# M051DN_v1 register map
File version: 1.0
Registers are 32-bit, read-write, reset 0x0 unless marked. A register's access mark holds for its fields unless they carry their own. Offsets are from the block's base; [hi:lo] are bit positions; {n}, {i} and the like mark numbered series.

## UART0 — UART Register Map
Base 0x40050000
Same registers: UART1 0x40150000
0x00 UA_RBR ro reset not defined — UART Receive Buffer Register
  [7:0] RBR — Receive Buffer Register (Read Only). By reading this register, the UART Controller will return an 8-bit data received from UART_RX pin (LSB first).
0x00 UA_THR wo reset not defined (alternate view of UA_RBR) — UART Transmit Holding Register
  [7:0] THR — Transmit Holding Register. By writing to this register, the UART Controller will send out an 8-bit data through the UART_ TX pin (LSB first).
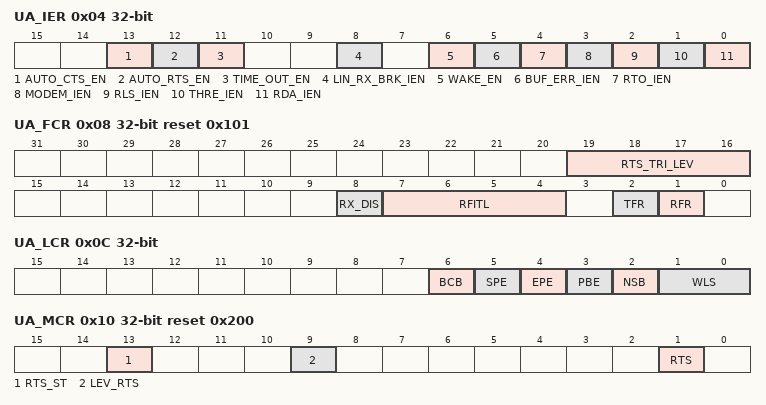
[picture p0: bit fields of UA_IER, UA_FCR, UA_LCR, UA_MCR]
0x04 UA_IER — UART Interrupt Enable Register
  [13] AUTO_CTS_EN — CTS Auto-flow Control Enable Control. Note: When CTS auto-flow is enabled, the UART will send data to external device when CTS input assert (UART will not send data to device until CTS is asserted).
    0=CTS auto-flow control Disabled; 1=CTS auto-flow control Enabled
  [12] AUTO_RTS_EN — RTS Auto-flow Control Enable Control. Note: When RTS auto-flow is enabled, if the number of bytes in the RX FIFO equals the RTS_TRI_LEV (UA_FCR [19:16]), the UART will reassert RTS signal.
    0=RTS auto-flow control Disabled; 1=RTS auto-flow control Enabled
  [11] TIME_OUT_EN — Time-out Counter Enable Control
    0=Time-out counter Disabled; 1=Time-out counter Enabled
  [8] LIN_RX_BRK_IEN — LIN RX Break Field Detected Interrupt Enable Control. Note: This bit is used for LIN function mode.
    0=LIN bus RX break filed interrupt Disabled; 1=LIN bus RX break filed interrupt Enabled
  [6] WAKE_EN — UART Wake-up Function Enable Control. Note: when the chip is in Power-down mode, an external CTS change will wake-up chip from Power-down mode.
    0=UART wake-up function Disabled; 1=UART wake-up function Enabled
  [5] BUF_ERR_IEN — Buffer Error Interrupt Enable Control
    0=BUF_ERR_INT Masked off; 1=BUF_ERR_INT Enabled
  [4] RTO_IEN — RX Time-out Interrupt Enable Control
    0=TOUT_INT Masked off; 1=TOUT_INT Enabled
  [3] MODEM_IEN — Modem Status Interrupt Enable Control
    0=MODEM_INT Masked off; 1=MODEM_INT Enabled
  [2] RLS_IEN — Receive Line Status Interrupt Enable Control
    0=RLS_INT Masked off; 1=RLS_INT Enabled
  [1] THRE_IEN — Transmit Holding Register Empty Interrupt Enable Control
    0=THRE_INT Masked off; 1=THRE_INT Enabled
  [0] RDA_IEN — Receive Data Available Interrupt Enable Control
    0=RDA_INT Masked off; 1=RDA_INT Enabled
0x08 UA_FCR reset 0x101 — UART FIFO Control Register
  [19:16] RTS_TRI_LEV — RTS Trigger Level (for Auto-flow Control Use). Note: This field is used for RTS auto-flow control.
    0=RTS Trigger Level is 1 byte; 1=RTS Trigger Level is 4 bytes; 2=RTS Trigger Level is 8 bytes; 3=RTS Trigger Level is 14 bytes
  [8] RX_DIS — Receiver Disable Register. The receiver is disabled or not (set 1 to disable receiver). Note: This field is used for RS-485 Normal Multi-drop mode. It should be programmed before RS-485_NMM (UA_ALT_CSR [8]) is programmed.
    0=Receiver Enabled; 1=Receiver Disabled
  [7:4] RFITL — RX FIFO Interrupt (RDA_INT) Trigger Level. When the number of bytes in the receive FIFO equals the RFITL then the RDA_IF will be set (if RDA_IEN in UA_IER register is enable, an interrupt will generated).
    0=RX FIFO Interrupt Trigger Level is 1 byte; 1=RX FIFO Interrupt Trigger Level is 4 bytes; 2=RX FIFO Interrupt Trigger Level is 8 bytes; 3=RX FIFO Interrupt Trigger Level is 14 bytes
  [2] TFR — TX Field Software Reset. When TX_RST is set, all the byte in the transmit FIFO and TX internal state machine are cleared. Note: This bit will automatically clear at least 3 UART Controller peripheral clock cycles.
    0=No effect; 1=Reset the TX internal state machine and pointers
  [1] RFR — RX Field Software Reset. When RX_RST is set, all the byte in the receiver FIFO and RX internal state machine are cleared. Note: This bit will automatically clear at least 3 UART Controller peripheral clock cycles.
    0=No effect; 1=Reset the RX internal state machine and pointers
0x0C UA_LCR — UART Line Control Register
  [6] BCB — Break Control Bit. When this bit is set to logic 1, the serial data output (TX) is forced to the Spacing State (logic 0). This bit acts only on TX and has no effect on the transmitter logic.
    0=Break control Disabled; 1=Break control Enabled
  [5] SPE — Stick Parity Enable Control
    0=Stick parity Disabled; 1=If PBE (UA_LCR[3]) and EBE (UA_LCR[4]) are logic 1, the parity bit is transmitted and checked as logic 0. If PBE (UA_LCR[3]) is 1 and EBE (UA_LCR[4]) is 0 then the parity bit is transmitted and checked as 1
  [4] EPE — Even Parity Enable Control. This bit has effect only when PBE (UA_LCR[3]) is set.
    0=Odd number of logic 1's is transmitted and checked in each word; 1=Even number of logic 1's is transmitted and checked in each word
  [3] PBE — Parity Bit Enable Control
    0=No parity bit; 1=Parity bit is generated on each outgoing character and is checked on each incoming data
  [2] NSB — Number of "STOP Bit"
    0=One "STOP bit" is generated in the transmitted data; 1=When select 5-bit word length, 1.5 "STOP bit" is generated in the transmitted data. When select 6-, 7- and 8-bti word length, 2 "STOP bit" is generated in the transmitted data
  [1:0] WLS — Word Length Selection
    {v}=Word length is {v+5}-bit (v=0..3)
0x10 UA_MCR reset 0x200 — UART Modem Control Register
  [13] RTS_ST ro — RTS Pin Status (Read Only). This bit mirror from RTS pin output of voltage logic status.
    0=RTS pin output is low level voltage logic state; 1=RTS pin output is high level voltage logic state
  [9] LEV_RTS — RTS Pin Active Level. This bit defines the active level state of RTS pin output. Note1: Refer to Figure 664 and Figure 665 for UART function mode. Note2: Refer to Figure 669 and Figure 670 for RS-485 function mode.
    0=RTS pin output is high level active; 1=RTS pin output is low level active
  [1] RTS — RTS (Request-to-send) Signal Control. This bit is direct control internal RTS signal active or not, and then drive the RTS pin output with LEV_RTS bit configuration. Note1: This RTS signal control bit is not effective when RTS auto-flow control is enabled in UART function mode. Note2: This RTS signal control bit is not effective when RS-485 auto direction mode (AUD) is enabled in RS-485 function mode.
    0=RTS signal is active; 1=RTS signal is inactive
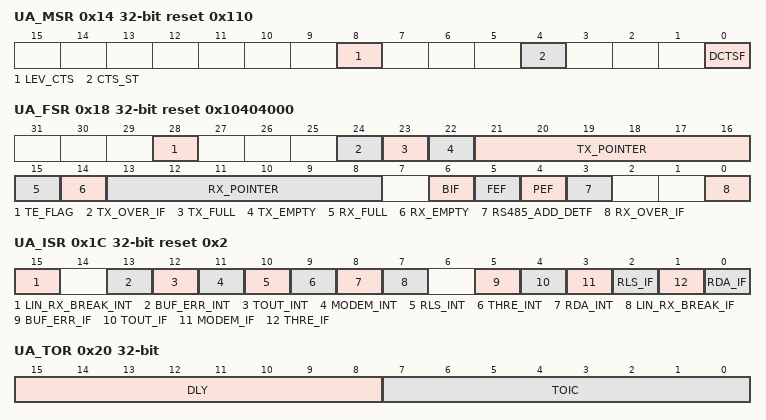
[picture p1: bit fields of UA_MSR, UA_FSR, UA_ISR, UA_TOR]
0x14 UA_MSR reset 0x110 — UART Modem Status Register
  [8] LEV_CTS — CTS Pin Active Level. This bit defines the active level state of CTS pin input. Note: Refer to Figure 663 for more information.
    0=CTS pin input is high level active; 1=CTS pin input is low level active
  [4] CTS_ST ro — CTS Pin Status (Read Only). This bit mirror from CTS pin input of voltage logic status. Note: This bit echoes when UART Controller peripheral clock is enabled, and CTS multi-function port is selected.
    0=CTS pin input is low level voltage logic state; 1=CTS pin input is high level voltage logic state
  [0] DCTSF — Detect CTS State Change Flag. This bit is set whenever CTS input has change state, and it will generate Modem interrupt to CPU when MODEM_IEN (UA_IER [3]) is set to 1. Note: This bit is cleared by writing 1 to it.
    0=CTS input has not change state; 1=CTS input has change state
0x18 UA_FSR reset 0x10404000 — UART FIFO Status Register
  [28] TE_FLAG ro — Transmitter Empty Flag (Read Only). This bit is set by hardware when TX FIFO (UA_THR) is empty and the STOP bit of the last byte has been transmitted. Note: This bit is cleared automatically when TX FIFO is not empty or the last byte transmission has not completed.
    0=TX FIFO is not empty; 1=TX FIFO is empty
  [24] TX_OVER_IF — TX Overflow Error Interrupt Flag. If TX FIFO (UA_THR) is full, an additional write to UA_THR will cause this bit to logic 1. Note: This bit is cleared by writing 1 to it.
    0=TX FIFO is not overflow; 1=TX FIFO is overflow
  [23] TX_FULL ro — Transmitter FIFO Full (Read Only). This bit indicates TX FIFO full or not. Note: This bit is set when the number of usage in TX FIFO Buffer is equal to 16, otherwise is cleared by hardware.
    0=TX FIFO is not full; 1=TX FIFO is full
  [22] TX_EMPTY ro — Transmitter FIFO Empty (Read Only). This bit indicates TX FIFO empty or not. Note: When the last byte of TX FIFO has been transferred to Transmitter Shift Register, hardware sets this bit high. It will be cleared when writing data into THR (TX FIFO not empty).
    0=TX FIFO is not empty; 1=TX FIFO is empty
  [21:16] TX_POINTER ro — TX FIFO Pointer (Read Only). This field indicates the TX FIFO Buffer Pointer. When CPU writes one byte into UA_THR, TX_POINTER increases one. When one byte of TX FIFO is transferred to Transmitter Shift Register, TX_POINTER decreases one. The Maximum value shown in TX_POINTER is 15. When the using level of TX FIFO Buffer equal to 16, the TX_FULL bit is set to 1 and TX_POINTER will show 0. As one byte of TX FIFO is transferred to Transmitter Shift Register, the TX_FULL bit is cleared to 0 and TX_POINTER will show 15.
  [15] RX_FULL ro — Receiver FIFO Full (Read Only). This bit initiates RX FIFO full or not. Note: This bit is set when the number of usage in RX FIFO Buffer is equal to 16, otherwise is cleared by hardware.
    0=RX FIFO is not full; 1=RX FIFO is full
  [14] RX_EMPTY ro — Receiver FIFO Empty (Read Only). This bit initiate RX FIFO empty or not. Note: When the last byte of RX FIFO has been read by CPU, hardware sets this bit high. It will be cleared when UART receives any new data.
    0=RX FIFO is not empty; 1=RX FIFO is empty
  [13:8] RX_POINTER ro — RX FIFO Pointer (Read Only). This field indicates the RX FIFO Buffer Pointer. When UART receives one byte from external device, RX_POINTER increases one. When one byte of RX FIFO is read by CPU, RX_POINTER decreases one. The Maximum value shown in RX_POINTER is 15. When the using level of RX FIFO Buffer equal to 16, the RX_FULL bit is set to 1 and RX_POINTER will show 0. As one byte of RX FIFO is read by CPU, the RX_FULL bit is cleared to 0 and RX_POINTER will show 15.
  [6] BIF ro — Break Interrupt Flag (Read Only). This bit is set to logic 1 whenever the received data input (RX) is held in the "spacing state" (logic 0) for longer than a full word transmission time (that is, the total time of "start bit" + data bits + parity + stop bits). Note1: This bit is read only, but can be cleared by writing '1' to it (M05xxDN/DE Only). Note2: This bit is read only, but can be cleared by writing '1' to RFR (UA_FCR [1]) (Available on M05xxBN and M05xxDN/DE).
    0=No Break interrupt is generated; 1=Break interrupt is generated
  [5] FEF ro — Framing Error Flag (Read Only). This bit is set to logic 1 whenever the received character does not have a valid "stop bit" (that is, the stop bit following the last data bit or parity bit is detected as logic 0). Note1: This bit is read only, but can be cleared by writing '1' to it (M05xxDN/DE Only). Note2: This bit is read only, but can be cleared by writing '1' to RFR (UA_FCR [1]) (Available on M05xxBN and M05xxDN/DE).
    0=No framing error is generated; 1=Framing error is generated
  [4] PEF ro — Parity Error Flag (Read Only). This bit is set to logic 1 whenever the received character does not have a valid "parity bit". Note1: This bit is read only, but can be cleared by writing '1' to it (M05xxDN/DE Only). Note2: This bit is read only, but can be cleared by writing '1' to RFR (UA_FCR [1]) (Available on M05xxBN and M05xxDN/DE).
    0=No parity error is generated; 1=Parity error is generated
  [3] RS485_ADD_DETF — RS-485 Address Byte Detection Flag. Note1: This field is used for RS-485 function mode. Note2: This bit is cleared by writing 1 to it.
  [0] RX_OVER_IF — RX Overflow Error Interrupt Flag. This bit is set when RX FIFO overflow. If the number of bytes of received data is greater than RX_FIFO (UA_RBR) size, 16 bytes this bit will be set. Note: This bit is cleared by writing 1 to it.
    0=RX FIFO is not overflow; 1=RX FIFO is overflow
0x1C UA_ISR reset 0x2 — UART Interrupt Status Register
  [15] LIN_RX_BREAK_INT ro — LIN Bus RX Break Field Detected Interrupt Indicator (Read Only). This bit is set if LIN_RX_BRK_IEN and LIN_RX_BREAK_IF are both set to 1.
    0=No LIN RX Break interrupt is generated; 1=LIN RX Break interrupt is generated
  [13] BUF_ERR_INT ro — Buffer Error Interrupt Indicator (Read Only). This bit is set if BUF_ERR_IEN and BUF_ERR_IF are both set to 1.
    0=No buffer error interrupt is generated; 1=buffer error interrupt is generated
  [12] TOUT_INT ro — Time-out Interrupt Indicator (Read Only). This bit is set if RTO_IEN and TOUT_IF are both set to 1.
    0=No Time-out interrupt is generated; 1=Time-out interrupt is generated
  [11] MODEM_INT ro — MODEM Status Interrupt Indicator (Read Only). This bit is set if MODEM_IEN and MODEM_IF are both set to 1.
    0=No Modem interrupt is generated; 1=Modem interrupt is generated
  [10] RLS_INT ro — Receive Line Status Interrupt Indicator (Read Only). This bit is set if RLS_IEN and RLS_IF are both set to 1.
    0=No RLS interrupt is generated; 1=RLS interrupt is generated
  [9] THRE_INT ro — Transmit Holding Register Empty Interrupt Indicator (Read Only). This bit is set if THRE_IEN and THRE_IF are both set to 1.
    0=No THRE interrupt is generated; 1=THRE interrupt is generated
  [8] RDA_INT ro — Receive Data Available Interrupt Indicator (Read Only). This bit is set if RDA_IEN and RDA_IF are both set to 1.
    0=No RDA interrupt is generated; 1=RDA interrupt is generated
  [7] LIN_RX_BREAK_IF — LIN Bus RX Break Field Detected Flag. This bit is set when RX received LIN Break Field. If LIN_RX_BRK_IEN (UA_IER [8]) is enabled the LIN RX Break interrupt will be generated. Note: This bit is cleared by writing 1 to it.
    0=No LIN RX Break received; 1=LIN RX Break received
  [5] BUF_ERR_IF ro — Buffer Error Interrupt Flag (Read Only). This bit is set when the TX/RX FIFO overflow flag (TX_OVER_IF or RX_OVER_IF) is set. On M05xxBN, this bit is also set when Break Interrupt Flag, Parity Error Flag or Frame Error Flag (BIF, PEF or FEF) is set. When BUF_ERR_IF is set, the transfer is not correct. If BUF_ERR_IEN (UA_IER [5]) is enabled, the buffer error interrupt will be generated. Note1: On M05xxDN/DE, this bit is read only and reset to 0 when all bits of TX_OVER_IF and RX_OVER_IF are cleared. (M05xxDN/DE Only). Note2: On M05xxBN, this bit is read only and reset to 0 when all bits of TX_OVER_IF, RX_OVER_IF, BIF, FEF and PEF are cleared. (M05xxBN Only)
    0=No buffer error interrupt flag is generated; 1=Buffer error interrupt flag is generated
  [4] TOUT_IF ro — Time-out Interrupt Flag (Read Only). This bit is set when the RX FIFO is not empty and no activities occurred in the RX FIFO and the time-out counter equal to TOIC. If RTO_IEN (UA_IER [4]) is enabled, the Tout interrupt will be generated. Note: This bit is read only and user can read UA_RBR (RX is in active) to clear it.
    0=No Time-out interrupt flag is generated; 1=Time-out interrupt flag is generated
  [3] MODEM_IF ro — MODEM Interrupt Flag (Read Only). Note: This bit is read only and reset to 0 when bit DCTSF is cleared by a write 1 on DCTSF.
    0=No Modem interrupt flag is generated; 1=Modem interrupt flag is generated
  [2] RLS_IF ro — Receive Line Interrupt Flag (Read Only). This bit is set when the RX receive data have parity error, framing error or break error (at least one of 3 bits, BIF, FEF and PEF, is set). If RLS_IEN (UA_IER [2]) is enabled, the RLS interrupt will be generated. Note2: This bit is read only and reset to 0 when all bits of BIF, FEF, PEF and RS485_ADD_DETF are cleared.
    0=No RLS interrupt flag is generated; 1=RLS interrupt flag is generated
  [1] THRE_IF ro — Transmit Holding Register Empty Interrupt Flag (Read Only). This bit is set when the last data of TX FIFO is transferred to Transmitter Shift Register. If THRE_IEN (UA_IER [1]) is enabled, the THRE interrupt will be generated. Note: This bit is read only and it will be cleared when writing data into THR (TX FIFO not empty).
    0=No THRE interrupt flag is generated; 1=THRE interrupt flag is generated
  [0] RDA_IF ro — Receive Data Available Interrupt Flag (Read Only). When the number of bytes in the RX FIFO equals the RFITL then the RDA_IF will be set. If RDA_IEN (UA_IER [0]) is enabled, the RDA interrupt will be generated. Note: This bit is read only and it will be cleared when the number of unread bytes of RX FIFO drops below the threshold level (RFITL).
    0=No RDA interrupt flag is generated; 1=RDA interrupt flag is generated
0x20 UA_TOR — UART Time-out Register
  [15:8] DLY — TX Delay Time Value. This field is use to programming the transfer delay time between the last stop bit and next start bit.
  [7:0] TOIC — Time-out Interrupt Comparator
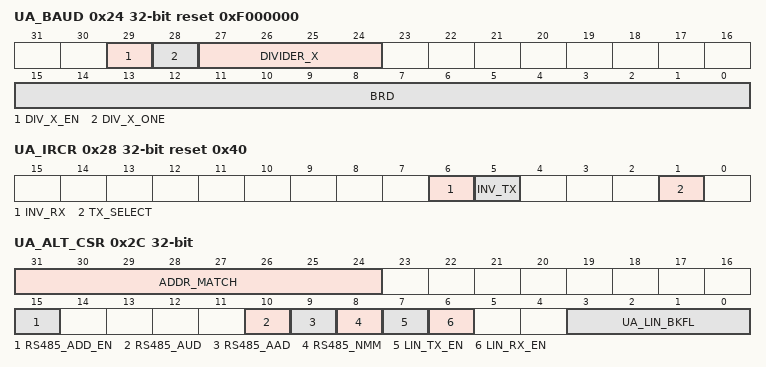
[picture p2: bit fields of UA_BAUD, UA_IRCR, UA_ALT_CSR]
0x24 UA_BAUD reset 0xF000000 — UART Baud Rate Divisor Register
  [29] DIV_X_EN — Divider X Enable Control. Note1: Refer to the section 6.11.5.1 for more information. Note2: In IrDA function mode, this bit must disable.
    0=Divider X Disabled (the equation of M = 16); 1=Divider X Enabled (the equation of M = X+1, but DIVIDER_X [27:24] must = 8)
  [28] DIV_X_ONE — Divider X Equal 1. Note1: Refer to the section 6.11.5.1 for more information.
    0=Divider M = X (the equation of M = X+1, but DIVIDER_X[27:24] must = 8); 1=Divider M = 1 (the equation of M = 1, but BRD [15:0] must = 8)
  [27:24] DIVIDER_X
  [15:0] BRD — Baud Rate Divider. The field indicated the baud rate divider.
0x28 UA_IRCR reset 0x40 — UART IrDA Control Register
  [6] INV_RX — Inverse RX Input Control
    0=No inversion; 1=Inverse RX input signal
  [5] INV_TX — Inverse RX Output Control
    0=No inversion; 1=Inverse TX output signal
  [1] TX_SELECT — IrDA Receiver Enable Control
    0=IrDA receiver Enabled; 1=IrDA transmitter Enabled
0x2C UA_ALT_CSR — UART Alternate Control/Status Register
  [31:24] ADDR_MATCH — Address Match Value Register. This field contains the RS-485 address match values. Note: This field is used for RS-485 auto address detection mode.
  [15] RS485_ADD_EN — RS-485 Address Detection Enable Control. This bit is use to enable RS-485 Address Detection mode. Note: This field is used for RS-485 any operation mode.
    0=RS-485 address detection mode Disabled; 1=RS-485 address detection mode Enabled
  [10] RS485_AUD — RS-485 Auto Direction Mode (AUD) Control. Note: It can be active with RS485_AAD or RS485_NMM operation mode.
    0=RS-485 Auto Direction Operation Mode (AUD) Disabled; 1=RS-485 Auto Direction Operation Mode (AUD) Enabled
  [9] RS485_AAD — RS-485 Auto Address Detection Operation Mode (AAD) Control. Note: It cannot be active with RS485_NMM operation mode.
    0=RS-485 Auto Address Detection Operation Mode (AAD) Disabled; 1=RS-485 Auto Address Detection Operation Mode (AAD) Enabled
  [8] RS485_NMM — RS-485 Normal Multi-drop Operation Mode (NMM) Control. Note: It cannot be active with RS485_AAD operation mode.
    0=RS-485 Normal Multi-drop Operation Mode (NMM) Disabled; 1=RS-485 Normal Multi-drop Operation Mode (NMM) Enabled
  [7] LIN_TX_EN — LIN TX Break Mode Enable Control. Note: When TX break field transfer operation finished, this bit will be cleared automatically.
    0=LIN TX Break Mode Disabled; 1=LIN TX Break Mode Enabled
  [6] LIN_RX_EN — LIN RX Enable Control
    0=LIN RX mode Disabled; 1=LIN RX mode Enabled
  [3:0] UA_LIN_BKFL — UART LIN Break Field Length. This field indicates a 4-bit LIN TX break field count. Note: This break field length is UA_LIN_BKFL + 2.
0x30 UA_FUN_SEL — UART Function Select Register
  [1:0] FUN_SEL — Function Select. UART Controller function mode selection.
    0=UART function mode; 1=LIN function mode; 2=IrDA function mode; 3=RS-485 function mode
